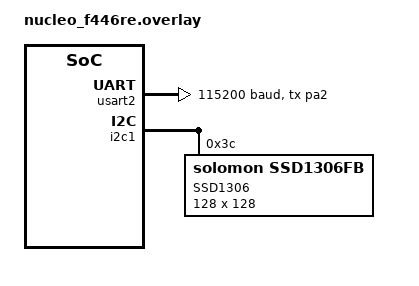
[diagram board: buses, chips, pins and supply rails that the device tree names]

/* SPDX-License-Identifier: Apache-2.0 */

/ {
    chosen {
        zephyr-display = &ssd1306_0;
    };

};

&usart2 {
	status = "okay";
	single-wire;

	pinctrl-0 = <&usart2_tx_pa2>;
	pinctrl-names = "default";
	current-speed = <115200>;
};


&i2c1 {
	ssd1306_0:ssd1306@3c {
        compatible = "solomon,ssd1306fb";
        reg = <0x3c>;
        label = "SSD1306";
        width = <128>;
        height = <128>;
        segment-offset = <0>;
        page-offset = <0>;
        display-offset = <0>;
        multiplex-ratio = <63>;
        //segment-remap;
        //com-invdir;
        //prechargep = <0x22>;
        prechargep = <0xD1>;
    };
};
